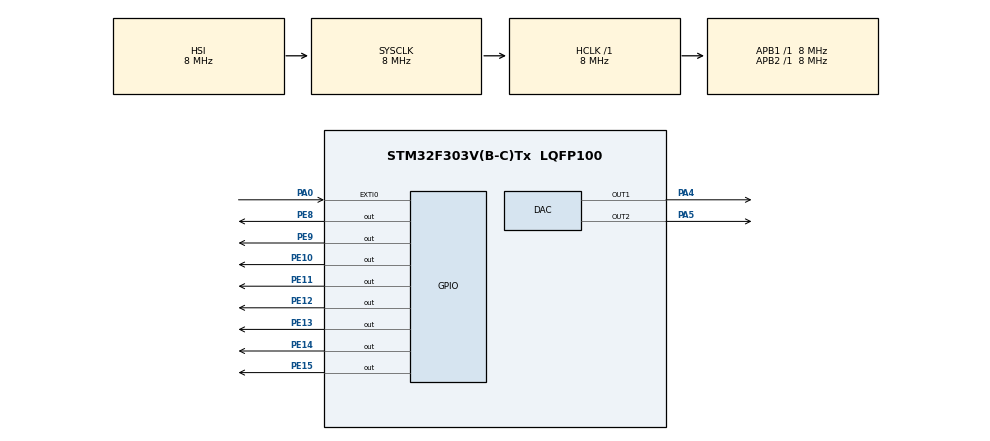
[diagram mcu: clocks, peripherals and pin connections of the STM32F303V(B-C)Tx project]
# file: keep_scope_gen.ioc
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DAC.DAC_Trigger=DAC_TRIGGER_NONE
DAC.DAC_Trigger2=DAC_TRIGGER_NONE
Mcu.Family=STM32F3
Mcu.Name=STM32F303V(B-C)Tx
Mcu.Package=LQFP100
NVIC.EXTI0_IRQn=true\:0\:0\:false\:false\:true\:true\:true
NVIC.PriorityGroup=NVIC_PRIORITYGROUP_4
NVIC.TIM1_TRG_COM_TIM17_IRQn=true\:0\:0\:false\:false\:true\:false\:true
NVIC.TimeBase=TIM1_TRG_COM_TIM17_IRQn
NVIC.TimeBaseIP=TIM17
PA0.Signal=GPXTI0
PA13.Mode=Serial_Wire
PA13.Signal=SYS_JTMS-SWDIO
PA14.Mode=Serial_Wire
PA14.Signal=SYS_JTCK-SWCLK
PA4.Signal=COMP_DAC1_group
PA5.Signal=COMP_DAC2_group
PE10.Signal=GPIO_Output
PE11.Signal=GPIO_Output
PE12.Signal=GPIO_Output
PE13.Signal=GPIO_Output
PE14.Signal=GPIO_Output
PE15.Signal=GPIO_Output
PE8.Signal=GPIO_Output
PE9.Signal=GPIO_Output
ProjectManager.HeapSize=0x800
ProjectManager.StackSize=0x400
ProjectManager.TargetToolchain=Makefile
RCC.AHBFreq_Value=8000000
RCC.APB1Freq_Value=8000000
RCC.APB1TimFreq_Value=8000000
RCC.APB2Freq_Value=8000000
RCC.APB2TimFreq_Value=8000000
RCC.CortexFreq_Value=8000000
RCC.HCLKFreq_Value=8000000
RCC.HSE_VALUE=8000000
RCC.HSI_VALUE=8000000
RCC.LSE_VALUE=32768
RCC.SYSCLKFreq_VALUE=8000000
SH.COMP_DAC1_group.0=DAC_OUT1,DAC_OUT1
SH.COMP_DAC2_group.0=DAC_OUT2,Enable_DAC_OUT2
VP_SYS_VS_tim17.Mode=TIM17
board=custom

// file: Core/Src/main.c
/* USER CODE BEGIN Header */
/**
  ******************************************************************************
  * @file           : main.c
  * @brief          : Main program body
  ******************************************************************************
  * @attention
  *
  * <h2><center>&copy; Copyright (c) 2020 STMicroelectronics.
  * All rights reserved.</center></h2>
  *
  * This software component is licensed by ST under BSD 3-Clause license,
  * the "License"; You may not use this file except in compliance with the
  * License. You may obtain a copy of the License at:
  *                        opensource.org/licenses/BSD-3-Clause
  *
  ******************************************************************************
  */
/* USER CODE END Header */

#include "main.h"

/* USER CODE BEGIN Includes */
#include "keep_logo.h"
/* USER CODE END Includes */

DAC_HandleTypeDef hdac;

/* USER CODE BEGIN PV */
uint8_t page = 0;
/* USER CODE END PV */

void SystemClock_Config(void);
static void MX_GPIO_Init(void);
static void MX_DAC_Init(void);

int main(void)
{

  /* MCU Configuration--------------------------------------------------------*/

  /* Reset of all peripherals, Initializes the Flash interface and the Systick. */
  HAL_Init();

  /* Configure the system clock */
  SystemClock_Config();

  /* Initialize all configured peripherals */
  MX_GPIO_Init();
  MX_DAC_Init();
  /* USER CODE BEGIN 2 */
  HAL_DAC_Start(&hdac, DAC_CHANNEL_1);
  HAL_DAC_Start(&hdac, DAC_CHANNEL_2);
  initKeep();
  int ledCnt = 0;
  /* USER CODE END 2 */

  /* Infinite loop */
  while (1)
  {
    switch (page)
    {
    case 0:
      lissajousDemo();
      break;
    case 1:
      drawKeep();
      break;
    case 2:
      drawPFK();
      break;
    case 3:
      drawKeepResize();
      break;
    case 4:
      drawKeepRot();
      break;
    case 5:
      drawTBTC();
      break;
    default:
      page = 0;
      break;
    }

    ledCnt++;
    if (ledCnt > 10)
    {
      ledCnt = 0;
      HAL_GPIO_TogglePin(GPIOE, GPIO_PIN_9);
    }
  }
}

void SystemClock_Config(void)
{
  RCC_OscInitTypeDef RCC_OscInitStruct = {0};
  RCC_ClkInitTypeDef RCC_ClkInitStruct = {0};

  /** Initializes the CPU, AHB and APB busses clocks
  */
  RCC_OscInitStruct.OscillatorType = RCC_OSCILLATORTYPE_HSI;
  RCC_OscInitStruct.HSIState = RCC_HSI_ON;
  RCC_OscInitStruct.HSICalibrationValue = RCC_HSICALIBRATION_DEFAULT;
  RCC_OscInitStruct.PLL.PLLState = RCC_PLL_NONE;
  if (HAL_RCC_OscConfig(&RCC_OscInitStruct) != HAL_OK)
  {
    Error_Handler();
  }
  /** Initializes the CPU, AHB and APB busses clocks
  */
  RCC_ClkInitStruct.ClockType = RCC_CLOCKTYPE_HCLK|RCC_CLOCKTYPE_SYSCLK
                              |RCC_CLOCKTYPE_PCLK1|RCC_CLOCKTYPE_PCLK2;
  RCC_ClkInitStruct.SYSCLKSource = RCC_SYSCLKSOURCE_HSI;
  RCC_ClkInitStruct.AHBCLKDivider = RCC_SYSCLK_DIV1;
  RCC_ClkInitStruct.APB1CLKDivider = RCC_HCLK_DIV1;
  RCC_ClkInitStruct.APB2CLKDivider = RCC_HCLK_DIV1;

  if (HAL_RCC_ClockConfig(&RCC_ClkInitStruct, FLASH_LATENCY_0) != HAL_OK)
  {
    Error_Handler();
  }
}

static void MX_DAC_Init(void)
{

  DAC_ChannelConfTypeDef sConfig = {0};

  /** DAC Initialization
  */
  hdac.Instance = DAC;
  if (HAL_DAC_Init(&hdac) != HAL_OK)
  {
    Error_Handler();
  }
  /** DAC channel OUT1 config
  */
  sConfig.DAC_Trigger = DAC_TRIGGER_NONE;
  sConfig.DAC_OutputBuffer = DAC_OUTPUTBUFFER_ENABLE;
  if (HAL_DAC_ConfigChannel(&hdac, &sConfig, DAC_CHANNEL_1) != HAL_OK)
  {
    Error_Handler();
  }
  /** DAC channel OUT2 config
  */
  sConfig.DAC_Trigger = DAC_TRIGGER_NONE;
  if (HAL_DAC_ConfigChannel(&hdac, &sConfig, DAC_CHANNEL_2) != HAL_OK)
  {
    Error_Handler();
  }

}

static void MX_GPIO_Init(void)
{
  GPIO_InitTypeDef GPIO_InitStruct = {0};

  /* GPIO Ports Clock Enable */
  __HAL_RCC_GPIOA_CLK_ENABLE();
  __HAL_RCC_GPIOE_CLK_ENABLE();

  /*Configure GPIO pin Output Level */
  HAL_GPIO_WritePin(GPIOE, GPIO_PIN_8|GPIO_PIN_9|GPIO_PIN_10|GPIO_PIN_11
                          |GPIO_PIN_12|GPIO_PIN_13|GPIO_PIN_14|GPIO_PIN_15, GPIO_PIN_RESET);

  /*Configure GPIO pin : PA0 */
  GPIO_InitStruct.Pin = GPIO_PIN_0;
  GPIO_InitStruct.Mode = GPIO_MODE_IT_RISING;
  GPIO_InitStruct.Pull = GPIO_NOPULL;
  HAL_GPIO_Init(GPIOA, &GPIO_InitStruct);

  /*Configure GPIO pins : PE8 PE9 PE10 PE11
                           PE12 PE13 PE14 PE15 */
  GPIO_InitStruct.Pin = GPIO_PIN_8|GPIO_PIN_9|GPIO_PIN_10|GPIO_PIN_11
                          |GPIO_PIN_12|GPIO_PIN_13|GPIO_PIN_14|GPIO_PIN_15;
  GPIO_InitStruct.Mode = GPIO_MODE_OUTPUT_PP;
  GPIO_InitStruct.Pull = GPIO_NOPULL;
  GPIO_InitStruct.Speed = GPIO_SPEED_FREQ_LOW;
  HAL_GPIO_Init(GPIOE, &GPIO_InitStruct);

  /* EXTI interrupt init*/
  HAL_NVIC_SetPriority(EXTI0_IRQn, 0, 0);
  HAL_NVIC_EnableIRQ(EXTI0_IRQn);

}

/* USER CODE BEGIN 4 */
void setPixel(int16_t x, int16_t y)
{
  HAL_DAC_SetValue(&hdac, DAC_CHANNEL_1, DAC_ALIGN_12B_R, (x+0x07FF)); // add offset to DAC_range/2
  HAL_DAC_SetValue(&hdac, DAC_CHANNEL_2, DAC_ALIGN_12B_R, (y+0x07FF)); // add offset to DAC_range/2
}

void HAL_GPIO_EXTI_Callback(uint16_t GPIO_Pin)
{
  if(GPIO_Pin == GPIO_PIN_0) // If The INT Source Is EXTI Line9 (A9 Pin)
  {
	  //HAL_GPIO_TogglePin(GPIOE, GPIO_PIN_8); // Toggle The Output (LED) Pin
    page++;
  }
}
/* USER CODE END 4 */

void HAL_TIM_PeriodElapsedCallback(TIM_HandleTypeDef *htim)
{
  if (htim->Instance == TIM17) {
    HAL_IncTick();
  }
}

void Error_Handler(void)
{
}

/************************ (C) COPYRIGHT STMicroelectronics *****END OF FILE****/
